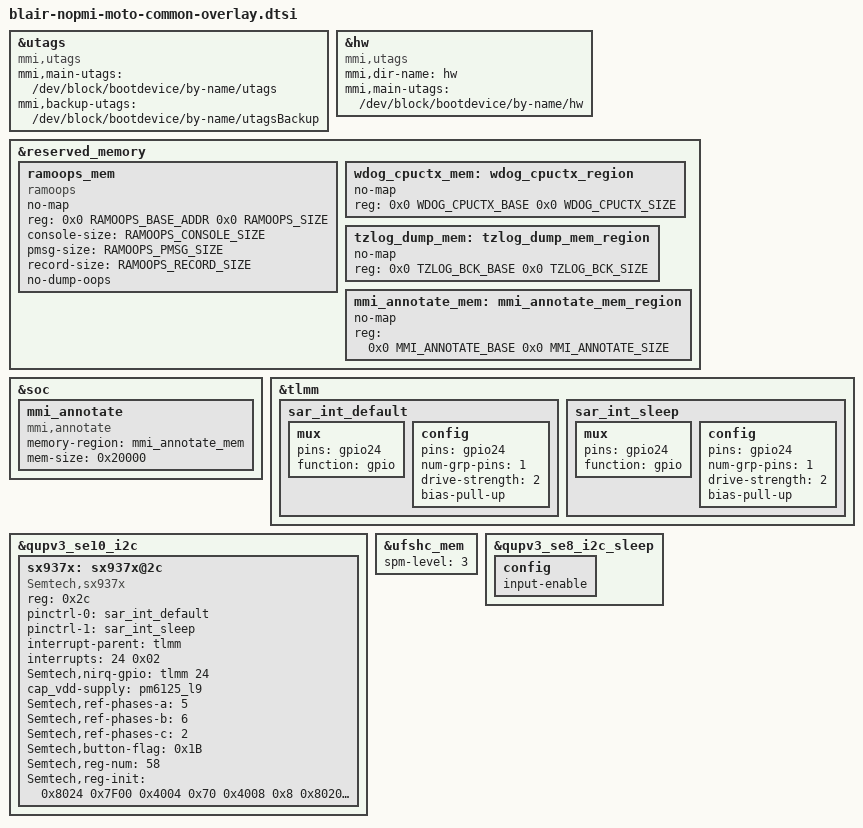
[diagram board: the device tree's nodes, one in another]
/* Copyright (c) 2020, The Linux Foundation. All rights reserved.
 *
 * This program is free software; you can redistribute it and/or modify
 * it under the terms of the GNU General Public License version 2 and
 * only version 2 as published by the Free Software Foundation.
 *
 * This program is distributed in the hope that it will be useful,
 * but WITHOUT ANY WARRANTY; without even the implied warranty of
 * MERCHANTABILITY or FITNESS FOR A PARTICULAR PURPOSE.  See the
 * GNU General Public License for more details.
 */
#include "carrier-channel-ids.dtsi"
#include <dt-bindings/moto/moto-mem-reserve.h>

&utags {
	compatible = "mmi,utags";
	mmi,main-utags = "/dev/block/bootdevice/by-name/utags";
	mmi,backup-utags = "/dev/block/bootdevice/by-name/utagsBackup";
};

&hw {
	compatible = "mmi,utags";
	mmi,dir-name = "hw";
	mmi,main-utags = "/dev/block/bootdevice/by-name/hw";
};

&reserved_memory {
	ramoops_mem {
		compatible = "ramoops";
		no-map;
		reg = <0x0 RAMOOPS_BASE_ADDR 0x0 RAMOOPS_SIZE>;
		console-size = <RAMOOPS_CONSOLE_SIZE>;
		pmsg-size = <RAMOOPS_PMSG_SIZE>;
		record-size = <RAMOOPS_RECORD_SIZE>;
		no-dump-oops;
	};

	wdog_cpuctx_mem: wdog_cpuctx_region {
		no-map;
		reg = <0x0 WDOG_CPUCTX_BASE
				0x0 WDOG_CPUCTX_SIZE>;
	};

	tzlog_dump_mem: tzlog_dump_mem_region {
		no-map;
		reg = <0x0  TZLOG_BCK_BASE
				0x0 TZLOG_BCK_SIZE>;
	};

	mmi_annotate_mem: mmi_annotate_mem_region {
		no-map;
		reg = <0x0  MMI_ANNOTATE_BASE
				0x0 MMI_ANNOTATE_SIZE>;
	};
};

&soc {
	mmi_annotate {
		compatible = "mmi,annotate";
		memory-region = <&mmi_annotate_mem>;
		mem-size = <0x20000>;
	};
};

&tlmm {
	sar_int_default: sar_int_default {
			mux {
				pins = "gpio24";
				function =  "gpio";
			};
			config {
				pins = "gpio24";
				num-grp-pins = <1>;
				drive-strength = <2>;
				bias-pull-up;
			};
	};

	sar_int_sleep: sar_int_sleep {
			mux {
				pins = "gpio24";
				function =  "gpio";
			};
			config {
				pins = "gpio24";
				num-grp-pins = <1>;
				drive-strength = <2>;
				bias-pull-up;
			};
	};
};

&qupv3_se10_i2c {
	status = "okay";

	sx937x:sx937x@2c {
		compatible = "Semtech,sx937x";
		reg = <0x2c>;
		pinctrl-names = "default","sleep";
		pinctrl-0 = <&sar_int_default>;
		pinctrl-1 = <&sar_int_sleep>;
		interrupt-parent = <&tlmm>;
		interrupts = <24 0x02>;
		interrupt-names = "sx937x_irq";
		Semtech,nirq-gpio = <&tlmm 24 0x02>;
		cap_vdd-supply = <&pm6125_l9>;
		/*use PH4/5/6 as the reference sensor
		set it to 0xff if the ref-phases-x is not used*/
		Semtech,ref-phases-a = <5>;
		Semtech,ref-phases-b = <6>;
		Semtech,ref-phases-c = <2>;
		Semtech,button-flag = <0x1B>;
		Semtech,reg-num = <58>;
		Semtech,reg-init = <
			0x8024  0x7F00
			0x4004  0x70
			0x4008  0x8
			0x8020  0x32
			0x8028  0x886 		/*AFE_PARAM_PH0*/
			0x8034  0x886 		/*AFE_PARAM_PH1*/
			0x8040  0x886 		/*AFE_PARAM_PH2*/
			0x804C  0x8BE    	/*AFE_PARAM_PH3*/
			0x8058  0x866 		/*AFE_PARAM_PH4*/
			0x8064  0x86E 		/*AFE_PARAM_PH5*/
			0x8070  0x86E 		/*AFE_PARAM_PH6*/
			0x807C  0x85E  		/*AFE_PARAM_PH7*/
			/*set CS3 to hiz, because it used as IRQ pin*/
			0x8030  0xFFF9FD 	/*REG_AFEPH_PH0, CS0, ANT1, Bottom center*/
			0x803C  0xFFD9FF 	/*REG_AFEPH_PH1, CS4, ANT2, Top right*/
			0x8048  0xFEF9FF 	/*REG_AFEPH_PH2, CS5, ANT7, Bottom Right*/
			0x8054  0xF7F9FF	/*REG_AFEPH_PH3, CS6, ANT4, Top Right*/
			0x8060  0xFFF97F 	/*REG_AFEPH_PH4, CS2, ANT5, Top center*/
			0x806C  0xFFF9EF 	/*REG_AFEPH_PH5, CS1, ANT1/7_REF, Bottom_Ref*/
			0x8078  0xBFF9FF 	/*REG_AFEPH_PH6, CS7, ANT4 REF, Middle*/
			0x8084  0xFFF9FF 	/*REG_AFEPH_PH7, NOT USE*/
			0x8098  0x7A36
			0x80B8  0x7636
			0x80D8  0xFF
			0x80F8  0x3939
			0x8118  0x2C2C
			0x8138  0xFF
			0x8158  0xFF
			0x8178  0x5A40
			0x80A0  0x1E1E00E1
			0x80C0  0x404000E2
			0x80E0  0x222200E1
			0x8100  0x161600E2
			0x8188  0x8000015
			0x818C  0x8000016
			0x8090  0x41DB3000
			0x80B0  0x7FB33000
			0x80D0  0x40CD3000
			0x80F0  0x68BD3000
			0x8110  0x30DD3000
			0x8130  0x2AD67000
			0x8150  0x2AD67000
			0x8170  0x2AD67000
			0x8088  0x300005
			0x80A8  0x300005
			0x80C8  0x2300005
			0x80E8  0x300005
			0x8108  0x300005
			0x8128  0x3600000
			0x8148  0x3600000
			0x8168  0x300000
			0x808C  0x60200060
			0x80AC  0x60200060
			0x80CC  0x60200060
			0x80EC  0x60200060
			0x810C  0x60200060
			0x812C  0x60200018
			0x814C  0x60200018
			0x816C  0x60200018
		>;

		status = "ok";
	};
};

&ufshc_mem {
	spm-level = <3>;
};

&qupv3_se8_i2c_sleep {
    config {
        input-enable;
    };
};
